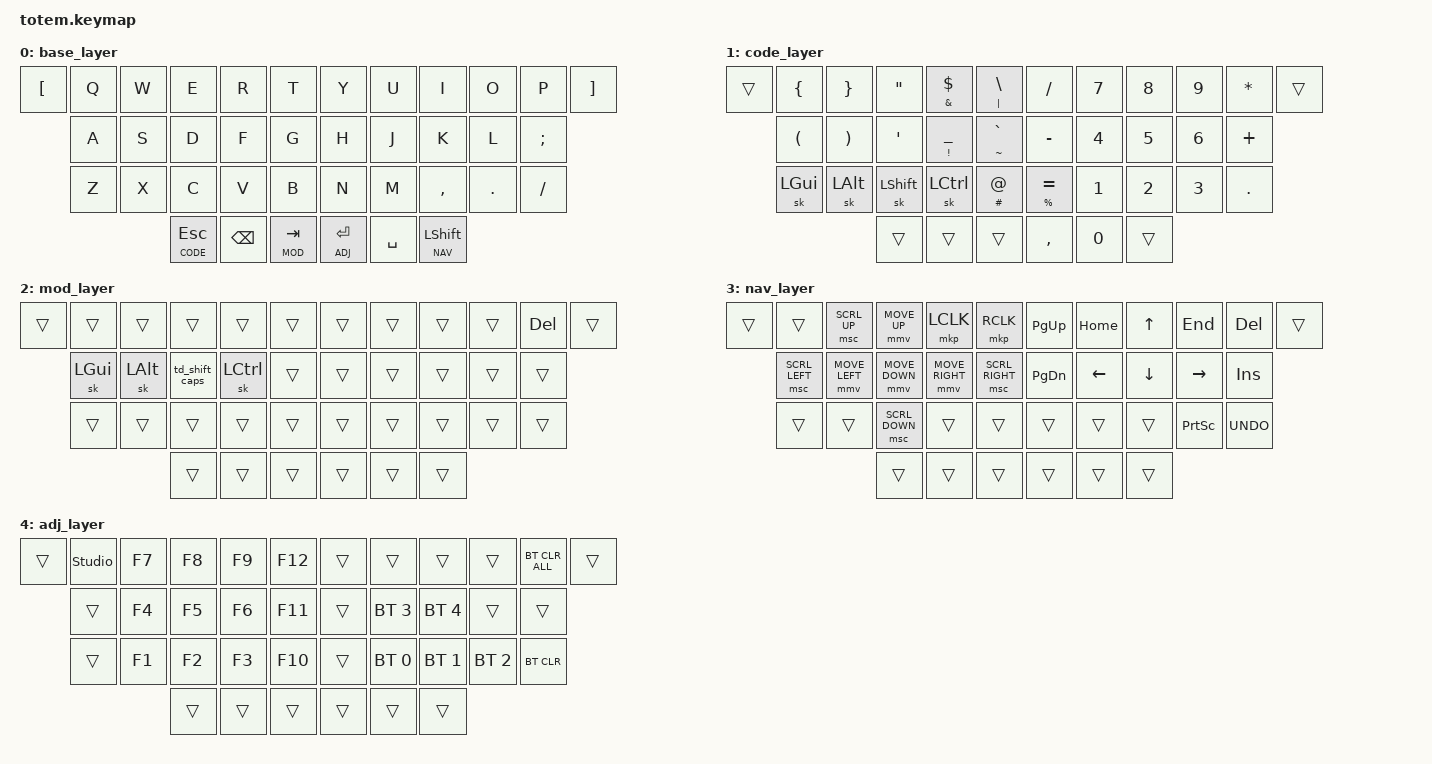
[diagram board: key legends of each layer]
#include <behaviors.dtsi>
#include <dt-bindings/zmk/keys.h>
#include <dt-bindings/zmk/bt.h>
#include <dt-bindings/zmk/mouse.h>

#define BASE 0
#define CODE 1
#define MOD  2
#define NAV  3
#define ADJ  4

/ {
    behaviors {
        td_eq_pct: equal_percent {
            compatible = "zmk,behavior-hold-tap";
            #binding-cells = <2>;
            tapping-term-ms = <200>;
            flavor = "tap-preferred";
            bindings = <&kp>, <&kp>;
        };
        
        td_us_ex: underscore_exclamation {
            compatible = "zmk,behavior-hold-tap";
            #binding-cells = <2>;
            tapping-term-ms = <200>;
            flavor = "tap-preferred";
            bindings = <&kp>, <&kp>;
        };
        
        td_dl_am: dollar_ampersand {
            compatible = "zmk,behavior-hold-tap";
            #binding-cells = <2>;
            tapping-term-ms = <200>;
            flavor = "tap-preferred";
            bindings = <&kp>, <&kp>;
        };
        
        td_at_hash: at_hash {
            compatible = "zmk,behavior-hold-tap";
            #binding-cells = <2>;
            tapping-term-ms = <200>;
            flavor = "tap-preferred";
            bindings = <&kp>, <&kp>;
        };
        
        td_bt_tl: backtick_tilde {
            compatible = "zmk,behavior-hold-tap";
            #binding-cells = <2>;
            tapping-term-ms = <200>;
            flavor = "tap-preferred";
            bindings = <&kp>, <&kp>;
        };
        
        td_bs_pipe: backslash_pipe {
            compatible = "zmk,behavior-hold-tap";
            #binding-cells = <2>;
            tapping-term-ms = <200>;
            flavor = "tap-preferred";
            bindings = <&kp>, <&kp>;
        };
        
        td_shift_caps: shift_caps {
            compatible = "zmk,behavior-tap-dance";
            #binding-cells = <0>;
            tapping-term-ms = <200>;
            bindings = <&kp LSHFT>, <&kp CAPS>;
        };
    };

    keymap {
        compatible = "zmk,keymap";

        base_layer {
            bindings = <
            &kp LBKT    &kp Q       &kp W       &kp E       &kp R       &kp T           &kp Y       &kp U       &kp I       &kp O       &kp P       &kp RBKT
                        &kp A       &kp S       &kp D       &kp F       &kp G           &kp H       &kp J       &kp K       &kp L       &kp SEMI
                        &kp Z       &kp X       &kp C       &kp V       &kp B           &kp N       &kp M       &kp COMMA   &kp DOT     &kp FSLH
                                                &lt CODE ESC &kp BSPC   &lt MOD TAB     &lt ADJ ENTER &kp SPACE &lt NAV LSHFT
            >;
        };

        code_layer {
            bindings = <
            &trans      &kp LBRC    &kp RBRC    &kp DQT     &td_dl_am AMPS DLLR   &td_bs_pipe PIPE BSLH     &kp FSLH    &kp N7      &kp N8      &kp N9      &kp STAR    &trans
                        &kp LPAR    &kp RPAR    &kp SQT     &td_us_ex EXCL UNDER  &td_bt_tl TILDE GRAVE     &kp MINUS   &kp N4      &kp N5      &kp N6      &kp PLUS
                        &sk LGUI    &sk LALT    &sk LSHFT   &sk LCTRL             &td_at_hash HASH AT       &td_eq_pct PRCNT EQUAL &kp N1 &kp N2 &kp N3      &kp DOT
                                                &trans      &trans      &trans      &kp COMMA   &kp N0      &trans
            >;
        };

        mod_layer {
            bindings = <
            &trans      &trans      &trans      &trans      &trans      &trans          &trans      &trans      &trans      &trans      &kp DEL     &trans
                        &sk LGUI    &sk LALT    &td_shift_caps &sk LCTRL &trans          &trans      &trans      &trans      &trans      &trans
                        &trans      &trans      &trans      &trans      &trans          &trans      &trans      &trans      &trans      &trans
                                                &trans      &trans      &trans          &trans      &trans      &trans
            >;
        };

        nav_layer {
            bindings = <
            &trans      &trans      &msc SCRL_UP &mmv MOVE_UP &mkp LCLK  &mkp RCLK       &kp PG_UP   &kp HOME    &kp UP      &kp END     &kp DEL     &trans
                        &msc SCRL_LEFT &mmv MOVE_LEFT &mmv MOVE_DOWN &mmv MOVE_RIGHT &msc SCRL_RIGHT &kp PG_DN &kp LEFT &kp DOWN &kp RIGHT &kp INS
                        &trans      &trans      &msc SCRL_DOWN &trans   &trans          &trans      &trans      &trans      &kp PSCRN   &kp K_UNDO
                                                &trans      &trans      &trans          &trans      &trans      &trans
            >;
        };

        adj_layer {
            bindings = <
            &trans      &studio_unlock &kp F7   &kp F8      &kp F9      &kp F12         &trans      &trans      &trans      &trans      &bt BT_CLR_ALL &trans
                        &trans      &kp F4      &kp F5      &kp F6      &kp F11         &trans      &bt BT_SEL 3 &bt BT_SEL 4 &trans    &trans
                        &trans      &kp F1      &kp F2      &kp F3      &kp F10         &trans      &bt BT_SEL 0 &bt BT_SEL 1 &bt BT_SEL 2 &bt BT_CLR
                                                &trans      &trans      &trans          &trans      &trans      &trans
            >;
        };
    };
};

&sk {
    release-after-ms = <2000>;
    quick-release;
};
